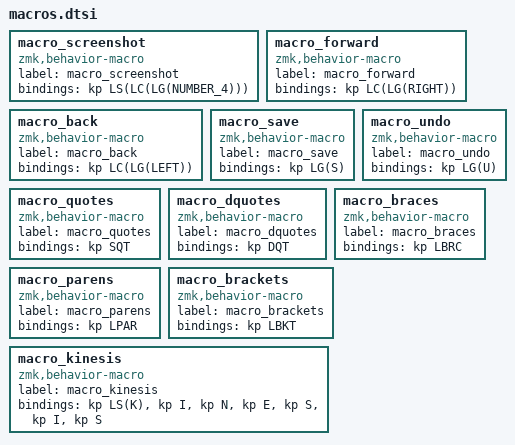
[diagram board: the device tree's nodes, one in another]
macro_screenshot: macro_screenshot{
compatible = "zmk,behavior-macro";
label = "macro_screenshot";
#binding-cells = <0>;
bindings = <&kt LSHIFT>, <&kt LCTRL>, <&kt LCMD>, <&kp NUMBER_4>, <&kt LCMD>, <&kt LCTRL>, <&kt LSHFT>;
bindings = <&kp LS(LC(LG(NUMBER_4)))>;
};
macro_forward: macro_forward{
compatible = "zmk,behavior-macro";
label = "macro_forward";
#binding-cells = <0>;
bindings = <&kp LC(LG(RIGHT))>;
};
macro_back: macro_back{
compatible = "zmk,behavior-macro";
label = "macro_back";
#binding-cells = <0>;
bindings = <&kp LC(LG(LEFT))>;
};
macro_save: macro_save{
compatible = "zmk,behavior-macro";
label = "macro_save";
#binding-cells = <0>;
bindings = <&kp LG(S)>;
};
macro_undo: macro_undo{
compatible = "zmk,behavior-macro";
label = "macro_undo";
#binding-cells = <0>;
bindings = <&kp LG(U)>;
};
macro_quotes: macro_quotes{
compatible = "zmk,behavior-macro";
label = "macro_quotes";
#binding-cells = <0>;
bindings = <&kp SQT>;
};
macro_dquotes: macro_dquotes{
compatible = "zmk,behavior-macro";
label = "macro_dquotes";
#binding-cells = <0>;
bindings = <&kp DQT>;
};
macro_braces: macro_braces{
compatible = "zmk,behavior-macro";
label = "macro_braces";
#binding-cells = <0>;
bindings = <&kp LBRC>;
};
macro_parens: macro_parens{
compatible = "zmk,behavior-macro";
label = "macro_parens";
#binding-cells = <0>;
bindings = <&kp LPAR>;
};
macro_brackets: macro_brackets{
compatible = "zmk,behavior-macro";
label = "macro_brackets";
#binding-cells = <0>;
bindings = <&kp LBKT>;
};
macro_kinesis: macro_kinesis{
compatible = "zmk,behavior-macro";
label = "macro_kinesis";
#binding-cells = <0>;
bindings = <&kp LS(K)>, <&kp I>, <&kp N>, <&kp E>, <&kp S>, <&kp I>, <&kp S>;
};
